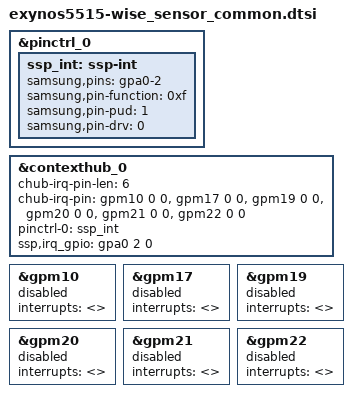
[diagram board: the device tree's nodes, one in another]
/*
 * SAMSUNG EXYNOS5515 sensor device tree source
 *
 * Copyright (c) 2021 Samsung Electronics Co., Ltd.
 *		http://www.samsung.com
 *
 * This program is free software; you can redistribute it and/or modify
 * it under the terms of the GNU General Public License version 2 as
 * published by the Free Software Foundation.
*/

&pinctrl_0 {
	ssp_int: ssp-int {
		samsung,pins = "gpa0-2";
		samsung,pin-function = <0xf>;
		samsung,pin-pud = <1>; /* Pull-down */
		samsung,pin-drv = <0>; /* 1x */
	};
};

&contexthub_0 {
	chub-irq-pin-len = <6>;
	chub-irq-pin = <&gpm10 0 0>, <&gpm17 0 0>, <&gpm19 0 0>, <&gpm20 0 0>, <&gpm21 0 0>, <&gpm22 0 0>;
	pinctrl-names = "default";
	pinctrl-0 = <&ssp_int>;
	ssp,irq_gpio = <&gpa0 2 0>;
};

&gpm10 {
	interrupts = <>;
	status = "disabled";
};

&gpm17 {
	interrupts = <>;
	status = "disabled";
};

&gpm19 {
	interrupts = <>;
	status = "disabled";
};

&gpm20 {
	interrupts = <>;
	status = "disabled";
};

&gpm21 {
	interrupts = <>;
	status = "disabled";
};

&gpm22 {
	interrupts = <>;
	status = "disabled";
};
